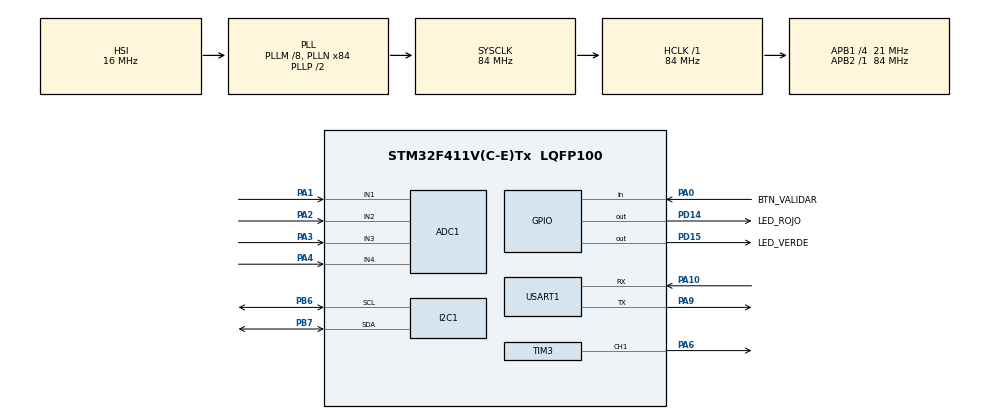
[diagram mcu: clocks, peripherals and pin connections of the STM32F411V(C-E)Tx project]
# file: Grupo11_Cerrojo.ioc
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ADC1.Channel-0\#ChannelRegularConversion=ADC_CHANNEL_1
ADC1.NbrOfConversionFlag=1
ADC1.Rank-0\#ChannelRegularConversion=1
ADC1.SamplingTime-0\#ChannelRegularConversion=ADC_SAMPLETIME_3CYCLES
ADC1.master=1
Mcu.Family=STM32F4
Mcu.Name=STM32F411V(C-E)Tx
Mcu.Package=LQFP100
NVIC.PriorityGroup=NVIC_PRIORITYGROUP_0
NVIC.TIM2_IRQn=true\:0\:0\:false\:false\:true\:true\:true\:true
PA0-WKUP.GPIO_Label=BTN_VALIDAR
PA0-WKUP.Signal=GPIO_Input
PA1.Signal=ADCx_IN1
PA10.Mode=Asynchronous
PA10.Signal=USART1_RX
PA2.Signal=ADCx_IN2
PA3.Signal=ADCx_IN3
PA4.Signal=ADCx_IN4
PA6.Signal=S_TIM3_CH1
PA9.Mode=Asynchronous
PA9.Signal=USART1_TX
PB6.Mode=I2C
PB6.Signal=I2C1_SCL
PB7.Mode=I2C
PB7.Signal=I2C1_SDA
PD14.GPIO_Label=LED_ROJO
PD14.Signal=GPIO_Output
PD15.GPIO_Label=LED_VERDE
PD15.Signal=GPIO_Output
ProjectManager.HeapSize=0x200
ProjectManager.StackSize=0x400
ProjectManager.TargetToolchain=STM32CubeIDE
RCC.48MHZClocksFreq_Value=21000000
RCC.AHBFreq_Value=84000000
RCC.APB1CLKDivider=RCC_HCLK_DIV4
RCC.APB1Freq_Value=21000000
RCC.APB1TimFreq_Value=42000000
RCC.APB2Freq_Value=84000000
RCC.APB2TimFreq_Value=84000000
RCC.CortexFreq_Value=84000000
RCC.HCLKFreq_Value=84000000
RCC.HSE_VALUE=8000000
RCC.HSI_VALUE=16000000
RCC.PLLI2SM=5
RCC.PLLI2SN=200
RCC.PLLM=8
RCC.PLLN=84
RCC.PLLQ=8
RCC.SYSCLKFreq_VALUE=84000000
RCC.SYSCLKSource=RCC_SYSCLKSOURCE_PLLCLK
RCC.VCOOutputFreq_Value=168000000
SH.ADCx_IN1.0=ADC1_IN1,IN1
SH.ADCx_IN2.0=ADC1_IN2,IN2
SH.ADCx_IN3.0=ADC1_IN3,IN3
SH.ADCx_IN4.0=ADC1_IN4,IN4
SH.S_TIM3_CH1.0=TIM3_CH1,PWM Generation1 CH1
TIM2.Period=9999
TIM2.Prescaler=8399
TIM3.Channel-PWM\ Generation1\ CH1=TIM_CHANNEL_1
TIM3.Prescaler=83
USART1.VirtualMode=VM_ASYNC
VP_TIM2_VS_ClockSourceINT.Mode=Internal
board=STM32F411E-DISCO

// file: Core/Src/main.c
/* USER CODE BEGIN Header */
/**
  ******************************************************************************
  * @file           : main.c
  * @brief          : Main program body
  ******************************************************************************
  * @attention
  *
  * Copyright (c) 2025 STMicroelectronics.
  * All rights reserved.
  *
  * This software is licensed under terms that can be found in the LICENSE file
  * in the root directory of this software component.
  * If no LICENSE file comes with this software, it is provided AS-IS.
  *
  ******************************************************************************
  */
/* USER CODE END Header */
#include "main.h"

/* USER CODE BEGIN Includes */

#include "juego.h"
#include "inputs.h"
#include "display.h"
#include "audio.h"
#include "bluetooth.h"

/* USER CODE END Includes */

ADC_HandleTypeDef hadc1;

I2C_HandleTypeDef hi2c1;

TIM_HandleTypeDef htim2;
TIM_HandleTypeDef htim3;

UART_HandleTypeDef huart1;

void SystemClock_Config(void);
static void MX_GPIO_Init(void);
static void MX_I2C1_Init(void);
static void MX_ADC1_Init(void);
static void MX_TIM2_Init(void);
static void MX_TIM3_Init(void);
static void MX_USART1_UART_Init(void);

int main(void)
{

  /* MCU Configuration--------------------------------------------------------*/

  /* Reset of all peripherals, Initializes the Flash interface and the Systick. */
  HAL_Init();

  /* Configure the system clock */
  SystemClock_Config();

  /* Initialize all configured peripherals */
  MX_GPIO_Init();
  MX_I2C1_Init();
  MX_ADC1_Init();
  MX_TIM2_Init();
  MX_TIM3_Init();
  MX_USART1_UART_Init();
  /* USER CODE BEGIN 2 */

  // ARRANCAR EL RELOJ DE LA BOMBA (TIM2)
    HAL_TIM_Base_Start_IT(&htim2);

    //INICIAR MÓDULOS
    juego_iniciar();
    inputs_iniciar();
    display_iniciar();
    audio_iniciar();

  /* USER CODE END 2 */

  /* Infinite loop */
  while (1)
  {

	  juego_actualizar();

  }
}

void SystemClock_Config(void)
{
  RCC_OscInitTypeDef RCC_OscInitStruct = {0};
  RCC_ClkInitTypeDef RCC_ClkInitStruct = {0};

  /** Configure the main internal regulator output voltage
  */
  __HAL_RCC_PWR_CLK_ENABLE();
  __HAL_PWR_VOLTAGESCALING_CONFIG(PWR_REGULATOR_VOLTAGE_SCALE1);

  /** Initializes the RCC Oscillators according to the specified parameters
  * in the RCC_OscInitTypeDef structure.
  */
  RCC_OscInitStruct.OscillatorType = RCC_OSCILLATORTYPE_HSI;
  RCC_OscInitStruct.HSIState = RCC_HSI_ON;
  RCC_OscInitStruct.HSICalibrationValue = RCC_HSICALIBRATION_DEFAULT;
  RCC_OscInitStruct.PLL.PLLState = RCC_PLL_ON;
  RCC_OscInitStruct.PLL.PLLSource = RCC_PLLSOURCE_HSI;
  RCC_OscInitStruct.PLL.PLLM = 8;
  RCC_OscInitStruct.PLL.PLLN = 84;
  RCC_OscInitStruct.PLL.PLLP = RCC_PLLP_DIV2;
  RCC_OscInitStruct.PLL.PLLQ = 8;
  if (HAL_RCC_OscConfig(&RCC_OscInitStruct) != HAL_OK)
  {
    Error_Handler();
  }

  /** Initializes the CPU, AHB and APB buses clocks
  */
  RCC_ClkInitStruct.ClockType = RCC_CLOCKTYPE_HCLK|RCC_CLOCKTYPE_SYSCLK
                              |RCC_CLOCKTYPE_PCLK1|RCC_CLOCKTYPE_PCLK2;
  RCC_ClkInitStruct.SYSCLKSource = RCC_SYSCLKSOURCE_PLLCLK;
  RCC_ClkInitStruct.AHBCLKDivider = RCC_SYSCLK_DIV1;
  RCC_ClkInitStruct.APB1CLKDivider = RCC_HCLK_DIV4;
  RCC_ClkInitStruct.APB2CLKDivider = RCC_HCLK_DIV1;

  if (HAL_RCC_ClockConfig(&RCC_ClkInitStruct, FLASH_LATENCY_2) != HAL_OK)
  {
    Error_Handler();
  }
}

static void MX_ADC1_Init(void)
{

  ADC_ChannelConfTypeDef sConfig = {0};

  /** Configure the global features of the ADC (Clock, Resolution, Data Alignment and number of conversion)
  */
  hadc1.Instance = ADC1;
  hadc1.Init.ClockPrescaler = ADC_CLOCK_SYNC_PCLK_DIV4;
  hadc1.Init.Resolution = ADC_RESOLUTION_12B;
  hadc1.Init.ScanConvMode = DISABLE;
  hadc1.Init.ContinuousConvMode = DISABLE;
  hadc1.Init.DiscontinuousConvMode = DISABLE;
  hadc1.Init.ExternalTrigConvEdge = ADC_EXTERNALTRIGCONVEDGE_NONE;
  hadc1.Init.ExternalTrigConv = ADC_SOFTWARE_START;
  hadc1.Init.DataAlign = ADC_DATAALIGN_RIGHT;
  hadc1.Init.NbrOfConversion = 1;
  hadc1.Init.DMAContinuousRequests = DISABLE;
  hadc1.Init.EOCSelection = ADC_EOC_SINGLE_CONV;
  if (HAL_ADC_Init(&hadc1) != HAL_OK)
  {
    Error_Handler();
  }

  /** Configure for the selected ADC regular channel its corresponding rank in the sequencer and its sample time.
  */
  sConfig.Channel = ADC_CHANNEL_1;
  sConfig.Rank = 1;
  sConfig.SamplingTime = ADC_SAMPLETIME_3CYCLES;
  if (HAL_ADC_ConfigChannel(&hadc1, &sConfig) != HAL_OK)
  {
    Error_Handler();
  }

}

static void MX_I2C1_Init(void)
{

  hi2c1.Instance = I2C1;
  hi2c1.Init.ClockSpeed = 100000;
  hi2c1.Init.DutyCycle = I2C_DUTYCYCLE_2;
  hi2c1.Init.OwnAddress1 = 0;
  hi2c1.Init.AddressingMode = I2C_ADDRESSINGMODE_7BIT;
  hi2c1.Init.DualAddressMode = I2C_DUALADDRESS_DISABLE;
  hi2c1.Init.OwnAddress2 = 0;
  hi2c1.Init.GeneralCallMode = I2C_GENERALCALL_DISABLE;
  hi2c1.Init.NoStretchMode = I2C_NOSTRETCH_DISABLE;
  if (HAL_I2C_Init(&hi2c1) != HAL_OK)
  {
    Error_Handler();
  }

}

static void MX_TIM2_Init(void)
{

  TIM_ClockConfigTypeDef sClockSourceConfig = {0};
  TIM_MasterConfigTypeDef sMasterConfig = {0};

  htim2.Instance = TIM2;
  htim2.Init.Prescaler = 8399;
  htim2.Init.CounterMode = TIM_COUNTERMODE_UP;
  htim2.Init.Period = 9999;
  htim2.Init.ClockDivision = TIM_CLOCKDIVISION_DIV1;
  htim2.Init.AutoReloadPreload = TIM_AUTORELOAD_PRELOAD_DISABLE;
  if (HAL_TIM_Base_Init(&htim2) != HAL_OK)
  {
    Error_Handler();
  }
  sClockSourceConfig.ClockSource = TIM_CLOCKSOURCE_INTERNAL;
  if (HAL_TIM_ConfigClockSource(&htim2, &sClockSourceConfig) != HAL_OK)
  {
    Error_Handler();
  }
  sMasterConfig.MasterOutputTrigger = TIM_TRGO_RESET;
  sMasterConfig.MasterSlaveMode = TIM_MASTERSLAVEMODE_DISABLE;
  if (HAL_TIMEx_MasterConfigSynchronization(&htim2, &sMasterConfig) != HAL_OK)
  {
    Error_Handler();
  }

}

static void MX_TIM3_Init(void)
{

  TIM_MasterConfigTypeDef sMasterConfig = {0};
  TIM_OC_InitTypeDef sConfigOC = {0};

  htim3.Instance = TIM3;
  htim3.Init.Prescaler = 83;
  htim3.Init.CounterMode = TIM_COUNTERMODE_UP;
  htim3.Init.Period = 65535;
  htim3.Init.ClockDivision = TIM_CLOCKDIVISION_DIV1;
  htim3.Init.AutoReloadPreload = TIM_AUTORELOAD_PRELOAD_DISABLE;
  if (HAL_TIM_PWM_Init(&htim3) != HAL_OK)
  {
    Error_Handler();
  }
  sMasterConfig.MasterOutputTrigger = TIM_TRGO_RESET;
  sMasterConfig.MasterSlaveMode = TIM_MASTERSLAVEMODE_DISABLE;
  if (HAL_TIMEx_MasterConfigSynchronization(&htim3, &sMasterConfig) != HAL_OK)
  {
    Error_Handler();
  }
  sConfigOC.OCMode = TIM_OCMODE_PWM1;
  sConfigOC.Pulse = 0;
  sConfigOC.OCPolarity = TIM_OCPOLARITY_HIGH;
  sConfigOC.OCFastMode = TIM_OCFAST_DISABLE;
  if (HAL_TIM_PWM_ConfigChannel(&htim3, &sConfigOC, TIM_CHANNEL_1) != HAL_OK)
  {
    Error_Handler();
  }
  HAL_TIM_MspPostInit(&htim3);

}

static void MX_USART1_UART_Init(void)
{

  huart1.Instance = USART1;
  huart1.Init.BaudRate = 115200;
  huart1.Init.WordLength = UART_WORDLENGTH_8B;
  huart1.Init.StopBits = UART_STOPBITS_1;
  huart1.Init.Parity = UART_PARITY_NONE;
  huart1.Init.Mode = UART_MODE_TX_RX;
  huart1.Init.HwFlowCtl = UART_HWCONTROL_NONE;
  huart1.Init.OverSampling = UART_OVERSAMPLING_16;
  if (HAL_UART_Init(&huart1) != HAL_OK)
  {
    Error_Handler();
  }

}

static void MX_GPIO_Init(void)
{
  GPIO_InitTypeDef GPIO_InitStruct = {0};

  /* GPIO Ports Clock Enable */
  __HAL_RCC_GPIOA_CLK_ENABLE();
  __HAL_RCC_GPIOD_CLK_ENABLE();
  __HAL_RCC_GPIOB_CLK_ENABLE();

  /*Configure GPIO pin Output Level */
  HAL_GPIO_WritePin(GPIOD, LED_ROJO_Pin|LED_VERDE_Pin, GPIO_PIN_RESET);

  /*Configure GPIO pin : BTN_VALIDAR_Pin */
  GPIO_InitStruct.Pin = BTN_VALIDAR_Pin;
  GPIO_InitStruct.Mode = GPIO_MODE_INPUT;
  GPIO_InitStruct.Pull = GPIO_NOPULL;
  HAL_GPIO_Init(BTN_VALIDAR_GPIO_Port, &GPIO_InitStruct);

  /*Configure GPIO pins : LED_ROJO_Pin LED_VERDE_Pin */
  GPIO_InitStruct.Pin = LED_ROJO_Pin|LED_VERDE_Pin;
  GPIO_InitStruct.Mode = GPIO_MODE_OUTPUT_PP;
  GPIO_InitStruct.Pull = GPIO_NOPULL;
  GPIO_InitStruct.Speed = GPIO_SPEED_FREQ_LOW;
  HAL_GPIO_Init(GPIOD, &GPIO_InitStruct);

}

void Error_Handler(void)
{
  __disable_irq();
  while (1)
  {
  }
}
